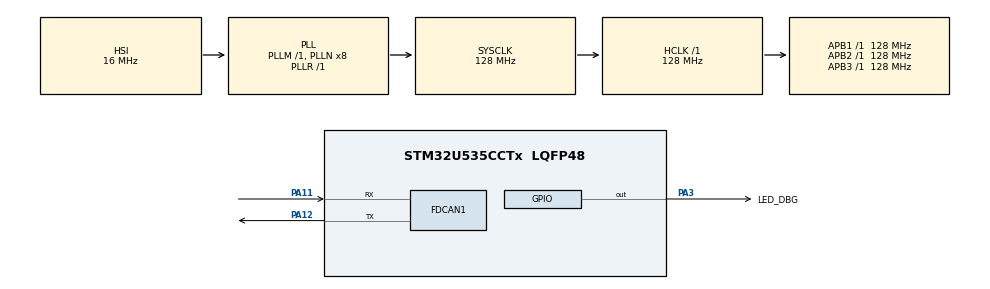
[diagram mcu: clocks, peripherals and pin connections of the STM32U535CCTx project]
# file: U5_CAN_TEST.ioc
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CORTEX_M33_NS.userName=CORTEX_M33
FDCAN1.AutoRetransmission=ENABLE
FDCAN1.CalculateBaudRateNominal=500000
FDCAN1.CalculateTimeBitNominal=2000
FDCAN1.CalculateTimeQuantumNominal=125.0
FDCAN1.NominalPrescaler=8
FDCAN1.NominalTimeSeg1=13
FDCAN1.NominalTimeSeg2=2
FDCAN1.StdFiltersNbr=1
Mcu.Family=STM32U5
Mcu.Name=STM32U535CCTx
Mcu.Package=LQFP48
NVIC.FDCAN1_IT0_IRQn=true\:0\:0\:false\:false\:true\:true\:true\:true
NVIC.FDCAN1_IT1_IRQn=true\:0\:0\:false\:false\:true\:true\:true\:true
NVIC.PriorityGroup=NVIC_PRIORITYGROUP_4
PA11.Mode=FDCAN_Activate
PA11.Signal=FDCAN1_RX
PA12.Mode=FDCAN_Activate
PA12.Signal=FDCAN1_TX
PA13\ (JTMS/SWDIO).Mode=Serial_Wire
PA13\ (JTMS/SWDIO).Signal=DEBUG_JTMS-SWDIO
PA14\ (JTCK/SWCLK).Mode=Serial_Wire
PA14\ (JTCK/SWCLK).Signal=DEBUG_JTCK-SWCLK
PA3.GPIO_Label=LED_DBG
PA3.Signal=GPIO_Output
ProjectManager.HeapSize=0x200
ProjectManager.StackSize=0x400
ProjectManager.TargetToolchain=STM32CubeIDE
RCC.ADCFreq_Value=16000000
RCC.AHBFreq_Value=128000000
RCC.APB1Freq_Value=128000000
RCC.APB1TimFreq_Value=128000000
RCC.APB2Freq_Value=128000000
RCC.APB2TimFreq_Value=128000000
RCC.APB3Freq_Value=128000000
RCC.CortexFreq_Value=128000000
RCC.DACCLockSelectionVirtual=RCC_DAC1CLKSOURCE_LSI
RCC.DACCLockSelectionVirtualString=RCC_DAC1CLKSOURCE_LSI
RCC.EPOD_VALUE=16000000
RCC.HCLKFreq_Value=128000000
RCC.HSE_VALUE=16000000
RCC.HSI48_VALUE=48000000
RCC.HSI_VALUE=16000000
RCC.LSE_VALUE=32768
RCC.LSIDIV_VALUE=32000
RCC.MSI_VALUE=4000000
RCC.PLL1R=1
RCC.PLLN=8
RCC.PLLSourceVirtual=RCC_PLLSOURCE_HSI
RCC.SYSCLKFreq_VALUE=128000000
RCC.SYSCLKSource=RCC_SYSCLKSOURCE_PLLCLK
RCC.USBFreq_Value=48000000
RCC.VCOOutputFreq_Value=128000000
VP_ICACHE_VS_ICACHE.Mode=DefaultMode
VP_LPBAMQUEUE_VS_QUEUE.Mode=QUEUEMODE
VP_LPBAM_VS_SIG1.Mode=SmartRun
VP_LPBAM_VS_SIG4.Mode=LPDMA1
VP_MEMORYMAP_VS_MEMORYMAP.Mode=CurAppReg
VP_PWR_VS_SECSignals.Mode=Security/Privilege
board=custom

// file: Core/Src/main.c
/* USER CODE BEGIN Header */
/**
  ******************************************************************************
  * @file           : main.c
  * @brief          : Main program body
  ******************************************************************************
  * @attention
  *
  * Copyright (c) 2026 STMicroelectronics.
  * All rights reserved.
  *
  * This software is licensed under terms that can be found in the LICENSE file
  * in the root directory of this software component.
  * If no LICENSE file comes with this software, it is provided AS-IS.
  *
  ******************************************************************************
  */
/* USER CODE END Header */
#include "main.h"

/* USER CODE BEGIN PD */
#define FDCAN_FILTER_ID1 0x000
#define FDCAN_FILTER_ID2 0x7FF

/* USER CODE END PD */

FDCAN_HandleTypeDef hfdcan1;

/* USER CODE BEGIN PV */
FDCAN_TxHeaderTypeDef TxHeader;
FDCAN_FilterTypeDef sFilterConfig;
FDCAN_RxHeaderTypeDef RxHeader;
uint8_t RxData[8] = {0};
uint8_t TxData[8] = {64};

void FDCAN_Restart() {
    if (HAL_FDCAN_Stop(&hfdcan1) != HAL_OK) {
    }
    if (HAL_FDCAN_Start(&hfdcan1) != HAL_OK) {
    }
}

HAL_StatusTypeDef FDCAN_SendMessage(uint32_t id, uint8_t *TxData) {
    TxHeader.Identifier = id;
    HAL_StatusTypeDef status = HAL_FDCAN_AddMessageToTxFifoQ(&hfdcan1, &TxHeader, TxData);
    if (status != HAL_OK) {
        uint32_t err = hfdcan1.ErrorCode;
        FDCAN_Restart();
    }
    return status;
}

/* USER CODE END PV */

void SystemClock_Config(void);
static void MX_GPIO_Init(void);
static void MX_FDCAN1_Init(void);
static void MX_ICACHE_Init(void);

int main(void)
{

  /* MCU Configuration--------------------------------------------------------*/

  /* Reset of all peripherals, Initializes the Flash interface and the Systick. */
  HAL_Init();

  /* Configure the system clock */
  SystemClock_Config();

  /* Initialize all configured peripherals */
  MX_GPIO_Init();
  MX_FDCAN1_Init();
  MX_ICACHE_Init();

  /* Infinite loop */
  /* USER CODE BEGIN WHILE */
  while (1)
  {
	  for (uint8_t k = 1; k < 60; ++k) {
		  uint8_t can_tx_data[8] = {k, k, k, k, k, k, k, k};
		  FDCAN_SendMessage(262, can_tx_data);
		  HAL_Delay(5);
	  }

	  HAL_Delay(5);
//	  HAL_GPIO_TogglePin(LED_DBG_GPIO_Port, LED_DBG_Pin);
    /* USER CODE END WHILE */

  }
}

void SystemClock_Config(void)
{
  RCC_OscInitTypeDef RCC_OscInitStruct = {0};
  RCC_ClkInitTypeDef RCC_ClkInitStruct = {0};

  /** Configure the main internal regulator output voltage
  */
  if (HAL_PWREx_ControlVoltageScaling(PWR_REGULATOR_VOLTAGE_SCALE1) != HAL_OK)
  {
    Error_Handler();
  }

  /** Initializes the CPU, AHB and APB buses clocks
  */
  RCC_OscInitStruct.OscillatorType = RCC_OSCILLATORTYPE_HSI;
  RCC_OscInitStruct.HSIState = RCC_HSI_ON;
  RCC_OscInitStruct.HSICalibrationValue = RCC_HSICALIBRATION_DEFAULT;
  RCC_OscInitStruct.PLL.PLLState = RCC_PLL_ON;
  RCC_OscInitStruct.PLL.PLLSource = RCC_PLLSOURCE_HSI;
  RCC_OscInitStruct.PLL.PLLMBOOST = RCC_PLLMBOOST_DIV1;
  RCC_OscInitStruct.PLL.PLLM = 1;
  RCC_OscInitStruct.PLL.PLLN = 8;
  RCC_OscInitStruct.PLL.PLLP = 2;
  RCC_OscInitStruct.PLL.PLLQ = 2;
  RCC_OscInitStruct.PLL.PLLR = 1;
  RCC_OscInitStruct.PLL.PLLRGE = RCC_PLLVCIRANGE_1;
  RCC_OscInitStruct.PLL.PLLFRACN = 0;
  if (HAL_RCC_OscConfig(&RCC_OscInitStruct) != HAL_OK)
  {
    Error_Handler();
  }

  /** Initializes the CPU, AHB and APB buses clocks
  */
  RCC_ClkInitStruct.ClockType = RCC_CLOCKTYPE_HCLK|RCC_CLOCKTYPE_SYSCLK
                              |RCC_CLOCKTYPE_PCLK1|RCC_CLOCKTYPE_PCLK2
                              |RCC_CLOCKTYPE_PCLK3;
  RCC_ClkInitStruct.SYSCLKSource = RCC_SYSCLKSOURCE_PLLCLK;
  RCC_ClkInitStruct.AHBCLKDivider = RCC_SYSCLK_DIV1;
  RCC_ClkInitStruct.APB1CLKDivider = RCC_HCLK_DIV1;
  RCC_ClkInitStruct.APB2CLKDivider = RCC_HCLK_DIV1;
  RCC_ClkInitStruct.APB3CLKDivider = RCC_HCLK_DIV1;

  if (HAL_RCC_ClockConfig(&RCC_ClkInitStruct, FLASH_LATENCY_3) != HAL_OK)
  {
    Error_Handler();
  }
}

static void MX_FDCAN1_Init(void)
{

  hfdcan1.Instance = FDCAN1;
  hfdcan1.Init.ClockDivider = FDCAN_CLOCK_DIV1;
  hfdcan1.Init.FrameFormat = FDCAN_FRAME_CLASSIC;
  hfdcan1.Init.Mode = FDCAN_MODE_NORMAL;
  hfdcan1.Init.AutoRetransmission = ENABLE;
  hfdcan1.Init.TransmitPause = DISABLE;
  hfdcan1.Init.ProtocolException = DISABLE;
  hfdcan1.Init.NominalPrescaler = 8;
  hfdcan1.Init.NominalSyncJumpWidth = 1;
  hfdcan1.Init.NominalTimeSeg1 = 13;
  hfdcan1.Init.NominalTimeSeg2 = 2;
  hfdcan1.Init.DataPrescaler = 1;
  hfdcan1.Init.DataSyncJumpWidth = 1;
  hfdcan1.Init.DataTimeSeg1 = 1;
  hfdcan1.Init.DataTimeSeg2 = 1;
  hfdcan1.Init.StdFiltersNbr = 1;
  hfdcan1.Init.ExtFiltersNbr = 0;
  hfdcan1.Init.TxFifoQueueMode = FDCAN_TX_FIFO_OPERATION;
  if (HAL_FDCAN_Init(&hfdcan1) != HAL_OK)
  {
    Error_Handler();
  }
  /* USER CODE BEGIN FDCAN1_Init 2 */
  sFilterConfig.IdType = FDCAN_STANDARD_ID;
  sFilterConfig.FilterIndex = 0;
  sFilterConfig.FilterType = FDCAN_FILTER_MASK;
  sFilterConfig.FilterConfig = FDCAN_FILTER_TO_RXFIFO0;
  sFilterConfig.FilterID1 = FDCAN_FILTER_ID1;
  sFilterConfig.FilterID2 = FDCAN_FILTER_ID2;

  if (HAL_FDCAN_ConfigFilter(&hfdcan1, &sFilterConfig) != HAL_OK){
      Error_Handler();
  }

  if (HAL_FDCAN_ActivateNotification(&hfdcan1, FDCAN_IT_RX_FIFO0_NEW_MESSAGE, 0) != HAL_OK){
      Error_Handler();
  }

  if (HAL_FDCAN_Start(&hfdcan1) != HAL_OK){
      Error_Handler();
  }

  HAL_NVIC_SetPriority(FDCAN1_IT0_IRQn, 0, 0);
  HAL_NVIC_EnableIRQ(FDCAN1_IT0_IRQn);
  HAL_NVIC_SetPriority(FDCAN1_IT1_IRQn, 0, 0);
  HAL_NVIC_EnableIRQ(FDCAN1_IT1_IRQn);

  TxHeader.Identifier = 0x000;
  TxHeader.IdType = FDCAN_STANDARD_ID;
  TxHeader.TxFrameType = FDCAN_DATA_FRAME;
  TxHeader.DataLength = FDCAN_DLC_BYTES_8;
  TxHeader.ErrorStateIndicator = FDCAN_ESI_ACTIVE;
  TxHeader.BitRateSwitch = FDCAN_BRS_OFF;
  TxHeader.FDFormat = FDCAN_CLASSIC_CAN;
  TxHeader.TxEventFifoControl = FDCAN_NO_TX_EVENTS;
  TxHeader.MessageMarker = 0;

  /* USER CODE END FDCAN1_Init 2 */

}

static void MX_ICACHE_Init(void)
{

  /** Enable instruction cache (default 2-ways set associative cache)
  */
  if (HAL_ICACHE_Enable() != HAL_OK)
  {
    Error_Handler();
  }

}

static void MX_GPIO_Init(void)
{
  GPIO_InitTypeDef GPIO_InitStruct = {0};

  /* GPIO Ports Clock Enable */
  __HAL_RCC_GPIOA_CLK_ENABLE();

  /*Configure GPIO pin Output Level */
  HAL_GPIO_WritePin(LED_DBG_GPIO_Port, LED_DBG_Pin, GPIO_PIN_RESET);

  /*Configure GPIO pin : LED_DBG_Pin */
  GPIO_InitStruct.Pin = LED_DBG_Pin;
  GPIO_InitStruct.Mode = GPIO_MODE_OUTPUT_PP;
  GPIO_InitStruct.Pull = GPIO_NOPULL;
  GPIO_InitStruct.Speed = GPIO_SPEED_FREQ_LOW;
  HAL_GPIO_Init(LED_DBG_GPIO_Port, &GPIO_InitStruct);

}

/* USER CODE BEGIN 4 */
void HAL_FDCAN_RxFifo0Callback(FDCAN_HandleTypeDef *hfdcan, uint32_t RxFifo0ITs){
    if ((RxFifo0ITs & FDCAN_IT_RX_FIFO0_NEW_MESSAGE) != RESET) {
        if (HAL_FDCAN_GetRxMessage(hfdcan, FDCAN_RX_FIFO0, &RxHeader, RxData) != HAL_OK) {
            return;
        }
    }
}

/* USER CODE END 4 */

void Error_Handler(void)
{
  __disable_irq();
  while (1)
  {
  }
}
